# ATSAME51J18A register map
Vendor: Microchip Technology; Series: SAME51; File version: 0
CPU: CM4 r0p1, selectable endian, MPU, FPU, 3 interrupt priority bits
Registers are 32-bit, read-write, reset 0x0 unless marked. A register's access mark holds for its fields unless they carry their own. Offsets are from the block's base; [hi:lo] are bit positions; {n}, {i} and the like mark numbered series.

## PAC — Peripheral Access Controller
Base 0x40000000; register names take the prefix PAC_
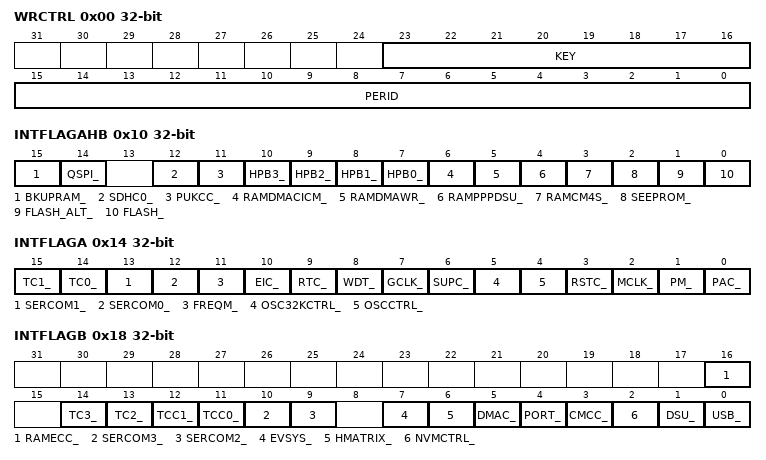
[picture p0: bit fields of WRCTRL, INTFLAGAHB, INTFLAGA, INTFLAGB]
0x00 WRCTRL — Write control
  [23:16] KEY — Peripheral access control key
    0=OFF (No action); 1=CLR (Clear protection); 2=SET (Set protection); 3=SETLCK (Set and lock protection)
  [15:0] PERID — Peripheral identifier
0x04 EVCTRL 8-bit — Event control
  [0] ERREO — Peripheral acess error event output
0x08 INTENCLR 8-bit — Interrupt enable clear
  [0] ERR — Peripheral access error interrupt disable
0x09 INTENSET 8-bit — Interrupt enable set
  [0] ERR — Peripheral access error interrupt enable
0x10 INTFLAGAHB — Bridge interrupt flag status
  [15] BKUPRAM_, [14] QSPI_ write-1-clears, [12] SDHC0_ write-1-clears, [11] PUKCC_ write-1-clears, [n+7] HPB{n}_ write-1-clears (n=0..3), [6] RAMDMACICM_ write-1-clears, [5] RAMDMAWR_ write-1-clears, [4] RAMPPPDSU_ write-1-clears, [3] RAMCM4S_ write-1-clears, [2] SEEPROM_ write-1-clears, [1] FLASH_ALT_ write-1-clears, [0] FLASH_ write-1-clears
0x14 INTFLAGA — Peripheral interrupt flag status - Bridge A
  [15] TC1_ write-1-clears, [14] TC0_ write-1-clears, [13] SERCOM1_ write-1-clears, [12] SERCOM0_ write-1-clears, [11] FREQM_ write-1-clears, [10] EIC_ write-1-clears, [9] RTC_ write-1-clears, [8] WDT_ write-1-clears, [7] GCLK_ write-1-clears, [6] SUPC_ write-1-clears, [5] OSC32KCTRL_ write-1-clears, [4] OSCCTRL_ write-1-clears, [3] RSTC_ write-1-clears, [2] MCLK_ write-1-clears, [1] PM_ write-1-clears, [0] PAC_ write-1-clears
0x18 INTFLAGB — Peripheral interrupt flag status - Bridge B
  [16] RAMECC_ write-1-clears, [14] TC3_ write-1-clears, [13] TC2_ write-1-clears, [12] TCC1_ write-1-clears, [11] TCC0_ write-1-clears, [10] SERCOM3_ write-1-clears, [9] SERCOM2_ write-1-clears, [7] EVSYS_ write-1-clears, [6] HMATRIX_, [5] DMAC_ write-1-clears, [4] PORT_ write-1-clears, [3] CMCC_ write-1-clears, [2] NVMCTRL_ write-1-clears, [1] DSU_ write-1-clears, [0] USB_ write-1-clears
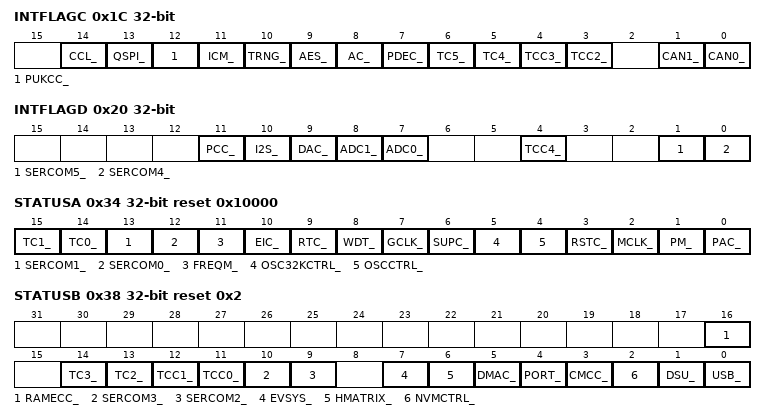
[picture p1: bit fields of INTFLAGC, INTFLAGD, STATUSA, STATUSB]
0x1C INTFLAGC — Peripheral interrupt flag status - Bridge C
  [14] CCL_ write-1-clears, [13] QSPI_ write-1-clears, [12] PUKCC_ write-1-clears, [11] ICM_ write-1-clears, [10] TRNG_ write-1-clears, [9] AES_ write-1-clears, [8] AC_ write-1-clears, [7] PDEC_ write-1-clears, [6] TC5_ write-1-clears, [5] TC4_ write-1-clears, [4] TCC3_ write-1-clears, [3] TCC2_ write-1-clears, [1] CAN1_ write-1-clears, [0] CAN0_ write-1-clears
0x20 INTFLAGD — Peripheral interrupt flag status - Bridge D
  [11] PCC_ write-1-clears, [10] I2S_ write-1-clears, [9] DAC_ write-1-clears, [8] ADC1_ write-1-clears, [7] ADC0_ write-1-clears, [4] TCC4_ write-1-clears, [1] SERCOM5_ write-1-clears, [0] SERCOM4_ write-1-clears
0x34 STATUSA ro reset 0x10000 — Peripheral write protection status - Bridge A
  [15] TC1_ — TC1 APB Protect Enable
  [14] TC0_ — TC0 APB Protect Enable
  [13] SERCOM1_ — SERCOM1 APB Protect Enable
  [12] SERCOM0_ — SERCOM0 APB Protect Enable
  [11] FREQM_ — FREQM APB Protect Enable
  [10] EIC_ — EIC APB Protect Enable
  [9] RTC_ — RTC APB Protect Enable
  [8] WDT_ — WDT APB Protect Enable
  [7] GCLK_ — GCLK APB Protect Enable
  [6] SUPC_ — SUPC APB Protect Enable
  [5] OSC32KCTRL_ — OSC32KCTRL APB Protect Enable
  [4] OSCCTRL_ — OSCCTRL APB Protect Enable
  [3] RSTC_ — RSTC APB Protect Enable
  [2] MCLK_ — MCLK APB Protect Enable
  [1] PM_ — PM APB Protect Enable
  [0] PAC_ — PAC APB Protect Enable
0x38 STATUSB ro reset 0x2 — Peripheral write protection status - Bridge B
  [16] RAMECC_ — RAMECC APB Protect Enable
  [14] TC3_ — TC3 APB Protect Enable
  [13] TC2_ — TC2 APB Protect Enable
  [12] TCC1_ — TCC1 APB Protect Enable
  [11] TCC0_ — TCC0 APB Protect Enable
  [10] SERCOM3_ — SERCOM3 APB Protect Enable
  [9] SERCOM2_ — SERCOM2 APB Protect Enable
  [7] EVSYS_ — EVSYS APB Protect Enable
  [6] HMATRIX_ — HMATRIX APB Protect Enable
  [5] DMAC_ — DMAC APB Protect Enable
  [4] PORT_ — PORT APB Protect Enable
  [3] CMCC_ — CMCC APB Protect Enable
  [2] NVMCTRL_ — NVMCTRL APB Protect Enable
  [1] DSU_ — DSU APB Protect Enable
  [0] USB_ — USB APB Protect Enable
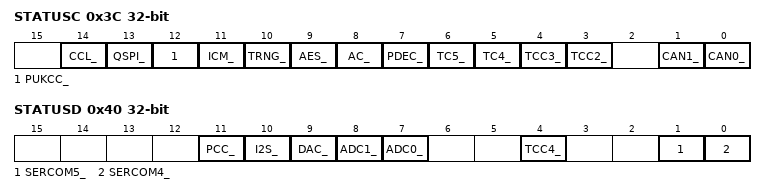
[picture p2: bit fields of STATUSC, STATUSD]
0x3C STATUSC ro — Peripheral write protection status - Bridge C
  [14] CCL_ — CCL APB Protect Enable
  [13] QSPI_ — QSPI APB Protect Enable
  [12] PUKCC_ — PUKCC APB Protect Enable
  [11] ICM_ — ICM APB Protect Enable
  [10] TRNG_ — TRNG APB Protect Enable
  [9] AES_ — AES APB Protect Enable
  [8] AC_ — AC APB Protect Enable
  [7] PDEC_ — PDEC APB Protect Enable
  [6] TC5_ — TC5 APB Protect Enable
  [5] TC4_ — TC4 APB Protect Enable
  [4] TCC3_ — TCC3 APB Protect Enable
  [3] TCC2_ — TCC2 APB Protect Enable
  [1] CAN1_ — CAN1 APB Protect Enable
  [0] CAN0_ — CAN0 APB Protect Enable
0x40 STATUSD ro — Peripheral write protection status - Bridge D
  [11] PCC_ — PCC APB Protect Enable
  [10] I2S_ — I2S APB Protect Enable
  [9] DAC_ — DAC APB Protect Enable
  [8] ADC1_ — ADC1 APB Protect Enable
  [7] ADC0_ — ADC0 APB Protect Enable
  [4] TCC4_ — TCC4 APB Protect Enable
  [1] SERCOM5_ — SERCOM5 APB Protect Enable
  [0] SERCOM4_ — SERCOM4 APB Protect Enable
